AUTOSAR XML (schema 4-0-3)
package /ComponentTypes
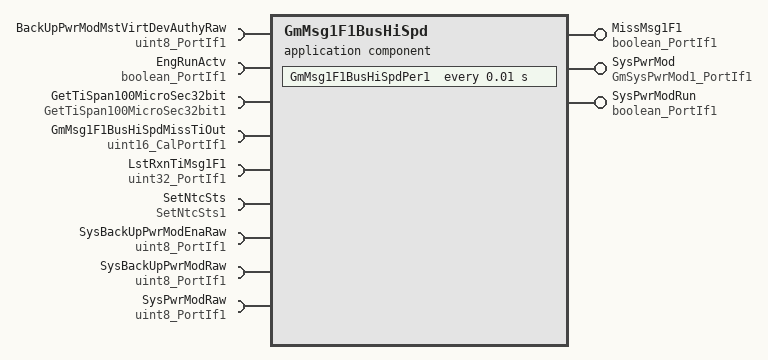
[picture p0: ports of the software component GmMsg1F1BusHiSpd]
  application sw component type GmMsg1F1BusHiSpd
    provide port MissMsg1F1: nonqueued-sender-com-spec{data-element=Logl, init-value=0}, provided-interface=boolean_PortIf1
    provide port SysPwrMod: nonqueued-sender-com-spec{data-element=Val, init-value=0}, provided-interface=GmSysPwrMod1_PortIf1
    provide port SysPwrModRun: nonqueued-sender-com-spec{data-element=Logl, init-value=0}, provided-interface=boolean_PortIf1
    9 x require port:
      BackUpPwrModMstVirtDevAuthyRaw: nonqueued-receiver-com-spec{data-element=Val, filter=data-filter-type=ALWAYS, init-value=0}, required-interface=uint8_PortIf1
      EngRunActv: nonqueued-receiver-com-spec{data-element=Logl, filter=data-filter-type=ALWAYS, init-value=0}, required-interface=boolean_PortIf1
      GetTiSpan100MicroSec32bit: required-interface=GetTiSpan100MicroSec32bit1
      GmMsg1F1BusHiSpdMissTiOut: parameter-require-com-spec{init-value=500, parameter=Val}, required-interface=uint16_CalPortIf1
      LstRxnTiMsg1F1: nonqueued-receiver-com-spec{data-element=Val, filter=data-filter-type=ALWAYS, init-value=0}, required-interface=uint32_PortIf1
      SetNtcSts: required-interface=SetNtcSts1
      SysBackUpPwrModEnaRaw: nonqueued-receiver-com-spec{data-element=Val, filter=data-filter-type=ALWAYS, init-value=0}, required-interface=uint8_PortIf1
      SysBackUpPwrModRaw: nonqueued-receiver-com-spec{data-element=Val, filter=data-filter-type=ALWAYS, init-value=0}, required-interface=uint8_PortIf1
      SysPwrModRaw: nonqueued-receiver-com-spec{data-element=Val, filter=data-filter-type=ALWAYS, init-value=0}, required-interface=uint8_PortIf1
    behavior GmMsg1F1BusHiSpd_InternalBehavior: data-type-mapping=Nexteer
      ar-typed-per-instance-memorys:
        data GmMsg1F1BusHiSpdPrevPrevSysPwrModRun: sw-calibration-access=READ-ONLY, type=boolean
      timing event TMT_GM1F1HSPer1: start-on-event=GmMsg1F1BusHiSpdPer1, period=0.01
      runnable GmMsg1F1BusHiSpdPer1
        data-receive-point-by-arguments:
          6 x access:
            REC_BackUpPwrModMstVirtDevAuthy_Val: accessed-variable=BackUpPwrModMstVirtDevAuthyRaw.Val
            REC_GM0C9HSEngRunActv_Logl: accessed-variable=EngRunActv.Logl
            REC_Msg1F1HSLstRxnTi_Val: accessed-variable=LstRxnTiMsg1F1.Val
            REC_SysBackUpPwrMod_Val: accessed-variable=SysBackUpPwrModRaw.Val
            REC_SysBackUpPwrModEna_Val: accessed-variable=SysBackUpPwrModEnaRaw.Val
            REC_SysPwrMod_Val: accessed-variable=SysPwrModRaw.Val
        data-send-points:
          access SEND_GM1F1HSSysPwrModRun_Logl: accessed-variable=SysPwrModRun.Logl
          access SEND_MissMsg1F1_Logl: accessed-variable=MissMsg1F1.Logl
          access SEND_SysPwrMod_Val: accessed-variable=SysPwrMod.Val
        sync call SC_GetTiSpan100MicroSec32bit_Oper: operation=GetTiSpan100MicroSec32bit.Oper, timeout=0
        sync call SC_SetNtcSts_Oper: operation=SetNtcSts.Oper, timeout=0
  swc implementation GmMsg1F1BusHiSpd_Implementation: behavior=GmMsg1F1BusHiSpd_InternalBehavior
    code-descriptors:
      code Default: artifact-descriptors=autosar-engineering-object={short-label=Default, category=SWSRC}
